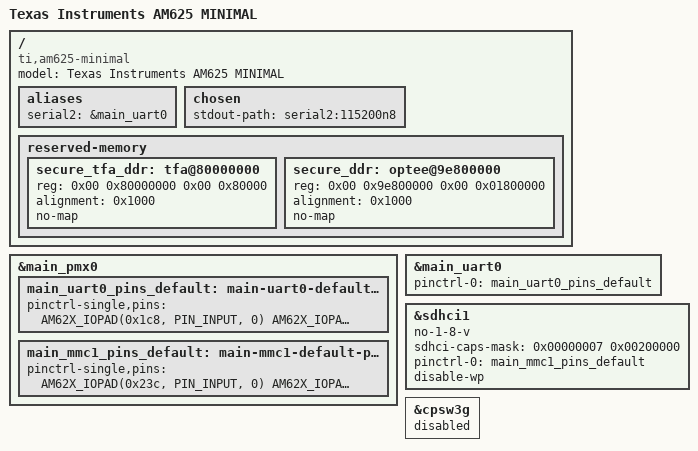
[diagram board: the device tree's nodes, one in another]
// SPDX-License-Identifier: GPL-2.0
/*
 * AM625 Minimal
 *
 * DT supports loading U-Boot binaries via UART and kernel image,
 * initramfs, and kernel devicetree through SD.
 *
 * Copyright (C) 2021-2024 Texas Instruments Incorporated - https://www.ti.com/
 */
/dts-v1/;

#include "k3-am625.dtsi"

/ {
	compatible = "ti,am625-minimal", "ti,am625";
	model = "Texas Instruments AM625 MINIMAL";

	aliases {
		serial2 = &main_uart0;
	};

	chosen {
		stdout-path = "serial2:115200n8";
	};

	reserved-memory {
		#address-cells = <2>;
		#size-cells = <2>;
		ranges;

		secure_tfa_ddr: tfa@80000000 {
			reg = <0x00 0x80000000 0x00 0x80000>;
			alignment = <0x1000>;
			no-map;
		};

		secure_ddr: optee@9e800000 {
			reg = <0x00 0x9e800000 0x00 0x01800000>;
			alignment = <0x1000>;
			no-map;
		};
	};
};

&main_pmx0 {
	/* First pad number is ALW package and second is AMC package */
	main_uart0_pins_default: main-uart0-default-pins {
		bootph-all;
		pinctrl-single,pins = <
			AM62X_IOPAD(0x1c8, PIN_INPUT, 0) /* (D14/A13) UART0_RXD */
			AM62X_IOPAD(0x1cc, PIN_OUTPUT, 0) /* (E14/E11) UART0_TXD */
		>;
	};

	main_mmc1_pins_default: main-mmc1-default-pins {
		bootph-all;
		pinctrl-single,pins = <
			AM62X_IOPAD(0x23c, PIN_INPUT, 0) /* (A21/C18) MMC1_CMD */
			AM62X_IOPAD(0x234, PIN_INPUT, 0) /* (B22/A20) MMC1_CLK */
			AM62X_IOPAD(0x230, PIN_INPUT, 0) /* (A22/A19) MMC1_DAT0 */
			AM62X_IOPAD(0x22c, PIN_INPUT, 0) /* (B21/B19) MMC1_DAT1 */
			AM62X_IOPAD(0x228, PIN_INPUT, 0) /* (C21/B20) MMC1_DAT2 */
			AM62X_IOPAD(0x224, PIN_INPUT, 0) /* (D22/C19) MMC1_DAT3 */
			AM62X_IOPAD(0x240, PIN_INPUT, 0) /* (D17/C15) MMC1_SDCD */
		>;
	};
};

&main_uart0 {
	bootph-all;
	status = "okay";
	pinctrl-names = "default";
	pinctrl-0 = <&main_uart0_pins_default>;
};

&sdhci1 {
	/* SD/MMC */
	bootph-all;
	status = "okay";
	no-1-8-v;
	sdhci-caps-mask = <0x00000007 0x00200000>;
	pinctrl-names = "default";
	pinctrl-0 = <&main_mmc1_pins_default>;
	disable-wp;
};

&cpsw3g {
	status = "disabled";
};
